# NPCX490M register map
File version: 1.0
Registers are 8-bit, read-write, reset 0x0 unless marked. A register's access mark holds for its fields unless they carry their own. Offsets are from the block's base; [hi:lo] are bit positions.

## CR_UART1
Base 0x400E0000
Same registers: CR_UART2 0x400E2000, CR_UART3 0x400E4000, CR_UART4 0x400E6000
0x00 UTBUFn wo — Transmit Data Buffer Register (UTBUFn)
0x02 URBUFn ro — Receive Data Buffer Register (URBUFn)
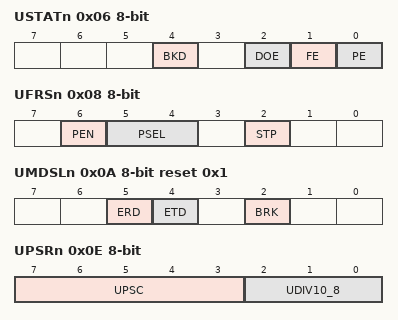
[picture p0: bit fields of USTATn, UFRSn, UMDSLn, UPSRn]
0x06 USTATn ro — Status Register (USTATn)
  [4] BKD — Break Detect
  [2] DOE — Data Overrun Error
  [1] FE — Framing Error
  [0] PE — Parity Error
0x08 UFRSn — Frame Select Register (UFRSn)
  [6] PEN — Parity Enable
  [5:4] PSEL — Parity Select
    0=Odd; 1=Even; 2=Mark; 3=Space
  [2] STP — Stop Bits
    0=OneBit; 1=TwoBits
0x0A UMDSLn reset 0x1 — Mode Select Register (UMDSLn)
  [5] ERD — Enable Receive DMA
  [4] ETD — Enable Transmit DMA
  [2] BRK — Break Transmit
0x0C UBAUDn — Baud Rate Divisor Register (UBAUDn)
0x0E UPSRn — Baud Rate Prescaler Register (UPSRn)
  [7:3] UPSC — Prescaler Select
  [2:0] UDIV10_8 — Baud Rate Divisor
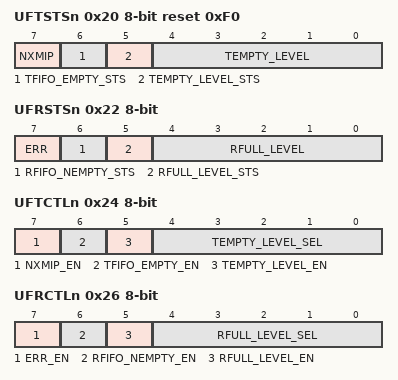
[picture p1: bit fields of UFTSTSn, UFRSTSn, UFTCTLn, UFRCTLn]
0x20 UFTSTSn ro reset 0xF0 — FIFO Mode Transmit Status Register (UFTSTSn)
  [7] NXMIP — No Transmit in Progress
  [6] TFIFO_EMPTY_STS — Transmit FIFO Empty Status
  [5] TEMPTY_LEVEL_STS — Transmit FIFO Empty Level Status
  [4:0] TEMPTY_LEVEL — Transmit FIFO Empty Level
0x22 UFRSTSn ro — FIFO Mode Receive Status Register (UFRSTSn)
  [7] ERR — Receive Error
  [6] RFIFO_NEMPTY_STS — Receive FIFO Not Empty Status
  [5] RFULL_LEVEL_STS — Receive FIFO Full Level Status
  [4:0] RFULL_LEVEL — Receive FIFO Full Level
0x24 UFTCTLn — FIFO Mode Transmit Control Register (UFTCTLn)
  [7] NXMIP_EN — No Transmit in Progress Interrupt Enable
  [6] TFIFO_EMPTY_EN — Transmit FIFO Empty Interrupt Enable
  [5] TEMPTY_LEVEL_EN — Transmit FIFO Empty Level Interrupt Enable
  [4:0] TEMPTY_LEVEL_SEL — Transmit FIFO Empty Level Select
0x26 UFRCTLn — FIFO Mode Receive Control Register (UFRCTLn)
  [7] ERR_EN — Receive Error Interrupt Enable
  [6] RFIFO_NEMPTY_EN — Receive FIFO Not Empty Interrupt Enable
  [5] RFULL_LEVEL_EN — Receive FIFO Full Level Interrupt Enable
  [4:0] RFULL_LEVEL_SEL — Receive FIFO Full Level Select
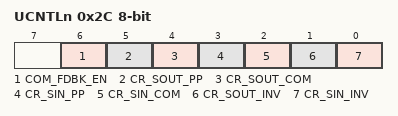
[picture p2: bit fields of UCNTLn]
0x2C UCNTLn — Control Register (UCNTLn)
  [6] COM_FDBK_EN — Common Mode Feedback Enable
  [5] CR_SOUT_PP — CR_SOUT Common Push-Pull Select
  [4] CR_SOUT_COM — CR_SOUT Common Mode Select
  [3] CR_SIN_PP — CR_SIN Common Push-Pull Select
  [2] CR_SIN_COM — CR_SIN Common Mode Select
  [1] CR_SOUT_INV — CR_SOUT Signal Invert
  [0] CR_SIN_INV — CR_SIN Signal Invert

## DEV
Base 0x400C3000
0x74 DBGCTRL — Debug Control Register (DBGCTRL)
  [4] SEQ_WK_EN — Wake-Up by Detection Sequence, Enable
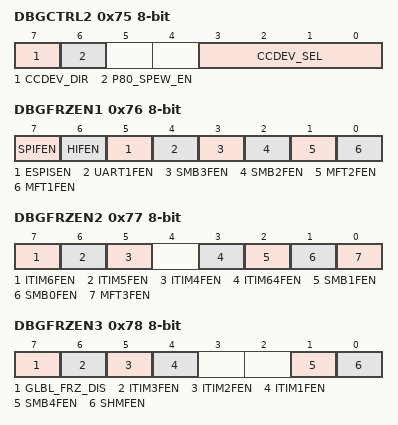
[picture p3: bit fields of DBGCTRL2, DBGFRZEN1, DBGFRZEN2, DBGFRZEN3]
0x75 DBGCTRL2 — Debug Control 2 Register (DBGCTRL2)
  [7] CCDEV_DIR — Closed Case Development Connector Direction
  [6] P80_SPEW_EN — Port80 Spew Enable
  [3:0] CCDEV_SEL — Closed Case Development Select
0x76 DBGFRZEN1 — Debug Freeze Enable 1 Register (DBGFRZEN1)
  [7] SPIFEN — SPI Peripheral Freeze Enable
  [6] HIFEN — Host Interface Freeze Enable
  [5] ESPISEN — eSPI Target Interface Freeze Enable
  [4] UART1FEN — CR_UART1 Freeze Enable
  [3] SMB3FEN — SMB3 Freeze Enable
  [2] SMB2FEN — SMB2 Freeze Enable
  [1] MFT2FEN — MFT16-2 Freeze Enable
  [0] MFT1FEN — MFT16-1 Freeze Enable
0x77 DBGFRZEN2 — Debug Freeze Enable 2 Register (DBGFRZEN2)
  [7] ITIM6FEN — ITIM32-6 Freeze Enable
  [6] ITIM5FEN — ITIM32-5 Freeze Enable
  [5] ITIM4FEN — ITIM32-4 Freeze Enable
  [3] ITIM64FEN — ITIM64 Freeze Enable
  [2] SMB1FEN — SMB1 Freeze Enable
  [1] SMB0FEN — SMB0 Freeze Enable
  [0] MFT3FEN — MFT16-3 Freeze Enable
0x78 DBGFRZEN3 — Debug Freeze Enable 3 Register (DBGFRZEN3)
  [7] GLBL_FRZ_DIS — Global Freeze Disable
  [6] ITIM3FEN — ITIM32-3 Freeze Enable
  [5] ITIM2FEN — ITIM32-2 Freeze Enable
  [4] ITIM1FEN — ITIM32-1 Freeze Enable
  [1] SMB4FEN — SMB4 Freeze Enable
  [0] SHMFEN — Shared Memory Freeze Enable
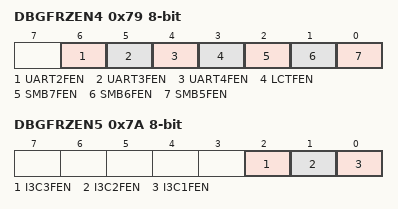
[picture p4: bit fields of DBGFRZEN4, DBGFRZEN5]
0x79 DBGFRZEN4 — Debug Freeze Enable 4 Register (DBGFRZEN4)
  [6] UART2FEN — CR_UART2 Freeze Enable
  [5] UART3FEN — CR_UART3 Freeze Enable
  [4] UART4FEN — CR_UART4 Freeze Enable
  [3] LCTFEN — LCT Freeze Enable
  [2] SMB7FEN — SMB7 Freeze Enable
  [1] SMB6FEN — SMB6 Freeze Enable
  [0] SMB5FEN — SMB5 Freeze Enable
0x7A DBGFRZEN5 — Debug Freeze Enable 5 Register (DBGFRZEN5)
  [2] I3C3FEN — I3CI3 Freeze Enable
  [1] I3C2FEN — I3CI2 Freeze Enable
  [0] I3C1FEN — I3CI1 Freeze Enable
